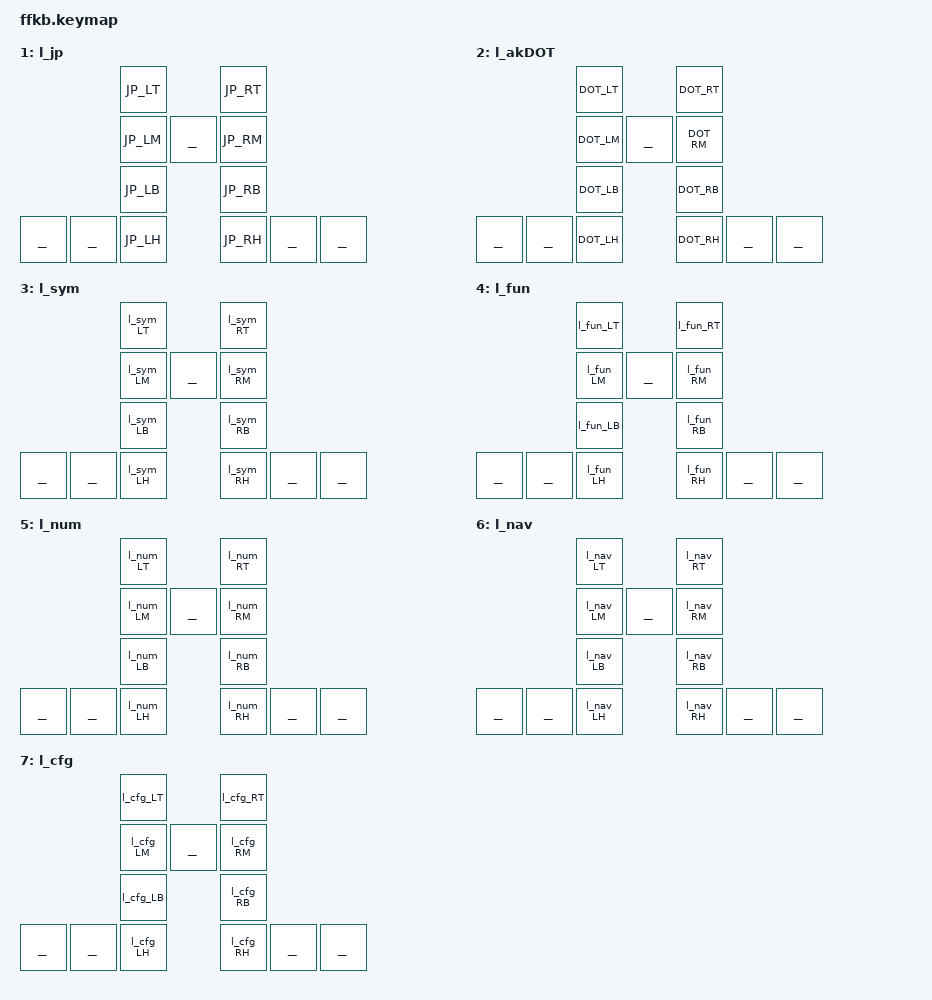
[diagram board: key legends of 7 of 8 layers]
/*
 * Copyright (c) 2022 The ZMK Contributors
 *
 * SPDX-License-Identifier: MIT
 */

#include <behaviors.dtsi>
#include <dt-bindings/zmk/keys.h>
#include <dt-bindings/zmk/rgb.h>
#include <dt-bindings/zmk/bt.h>
#include <dt-bindings/zmk/ext_power.h>
#include <dt-bindings/zmk/outputs.h>
#include <behaviors/num_word.dtsi>      // urob's num_word module


#include "moutis/moutis_config.dtsi"    // my add-on feature defs
#include "keymaps/keynames_3x5_2.h"     // keyname defs core alpha (3x5+2)
#include "keymaps/layers_def.h"         // layer def common core (3x5+2)
#include "layouts/hd/vf-config.h"       // HD alpha keymap, adapt, and combo definitions

&sensors {
        triggers-per-rotation = <40>;   // depends on the encoder
};
/ {
/*
 * Behaviors
 */
    behaviors {

#include "moutis/moutis_sensors.dtsi"   // EC11 & other sensor behaviors
#include "moutis/moutis_behaviors.dtsi" // common behaviors (hold-taps, mod-morphs, lingers, adaptives)
#include HD_adapt_file                  // HDalpha/mnemonic based adaptives (most of them)

    };

/*
 * Macros
 */
    macros {
    
#include "moutis/moutis_macros.dtsi"    // common macros (superset)

    };

/*
 * Combos
 */
    combos {
        compatible = "zmk,combos";

#include "moutis/moutis_combos.dtsi"    // common/location based combos (cut/copy/paste, esc, app, etc.)
#include HD_combo_file                  // HD alpha/mnemonic based combos (h-digraphs, etc.)

    };
/*
 * Keymap (all layers w/references to the above behaviors/macros/combos)
 */

    keymap {
        compatible = "zmk,keymap";
            l_alpha {
                label = HD_Layer_label;
                bindings = <
                                HD_LT               HD_RT
                                HD_LM    _______    HD_RM
                                HD_LB               HD_RB
          &kp C_MUTE  &SlAppy   HD_LH               HD_RH &tog l_num  &kp C_PP
                >;
                sensor-bindings = <&e_VolApp &e_PGApp>;
            };
            l_jp {
                label = JP_Layer_label;
                bindings = <
                                JP_LT               JP_RT
                                JP_LM    _______    JP_RM
                                JP_LB               JP_RB
                _______ _______ JP_LH               JP_RH _______   _______
                >;
                sensor-bindings = <&inc_dec_kp C_VOL_DN C_VOL_UP &inc_dec_kp PG_UP PG_DN>;
            };
            l_akDOT {
                label = l_akDOT_label;
                bindings = <
                                DOT_LT              DOT_RT
                                DOT_LM   _______    DOT_RM
                                DOT_LB              DOT_RB
                _______ _______ DOT_LH              DOT_RH _______  _______
                >;
            };

            l_sym {
            label = l_sym_label;
                bindings = <
                                l_sym_LT            l_sym_RT
                                l_sym_LM  _______   l_sym_RM
                                l_sym_LB            l_sym_RB
                _______ _______ l_sym_LH            l_sym_RH _______    _______
                >;
                sensor-bindings = <&inc_dec_kp S_WRDL S_WRDR &inc_dec_kp PG_UP PG_DN>;
            };

            l_fun {
                label = l_fun_label;
                bindings = <
                                l_fun_LT            l_fun_RT
                                l_fun_LM  _______   l_fun_RM
                                l_fun_LB            l_fun_RB
                _______ _______ l_fun_LH            l_fun_RH _______    _______
                >;
                sensor-bindings = <&inc_dec_kp C_VOL_DN C_VOL_UP &inc_dec_kp C_PREV C_NEXT>;
            };

            l_num {
                label = l_num_label;
                bindings = <
                                l_num_LT            l_num_RT
                                l_num_LM  _______   l_num_RM
                                l_num_LB            l_num_RB
                _______ _______ l_num_LH            l_num_RH _______    _______
                >;
                sensor-bindings = <&inc_dec_kp C_VOL_DN C_VOL_UP &inc_dec_kp PG_UP PG_DN>;
            };

            l_nav {
                label = l_nav_label;
                bindings = <
                                l_nav_LT            l_nav_RT
                                l_nav_LM  _______   l_nav_RM
                                l_nav_LB            l_nav_RB
                _______ _______ l_nav_LH            l_nav_RH _______    _______
                >;
                sensor-bindings = <&inc_dec_kp S_ZMIN S_ZMOUT &inc_dec_kp S_BBACK S_BFWD>;
            };

            l_cfg {
                label = l_cfg_label;
                bindings = <
                                l_cfg_LT            l_cfg_RT
                                l_cfg_LM  _______   l_cfg_RM
                                l_cfg_LB            l_cfg_RB
                _______ _______ l_cfg_LH            l_cfg_RH _______    _______
                >;
                sensor-bindings = <&inc_dec_kp C_BRI_UP C_BRI_DN  &inc_dec_kp S_ZMIN S_ZMOUT >;
            };
    };

};
